# UART6 register map
Registers from a debugger description file.
Registers are 32-bit, access not given, no defined reset value unless marked. A register's access mark holds for its fields unless they carry their own. Addresses are absolute; registers are grouped by the start of their names; lines under a group give offsets from that group; [hi:lo] are bit positions; {n}, {i} and the like mark numbered series; 'fields as' and 'values as' point back to an identical list; <NAME> marks a mode.

## UART6
0x50002000 UART6/DLL
  [7:0] DLL
0x50002000 UART6/THR
  [7:0] THR
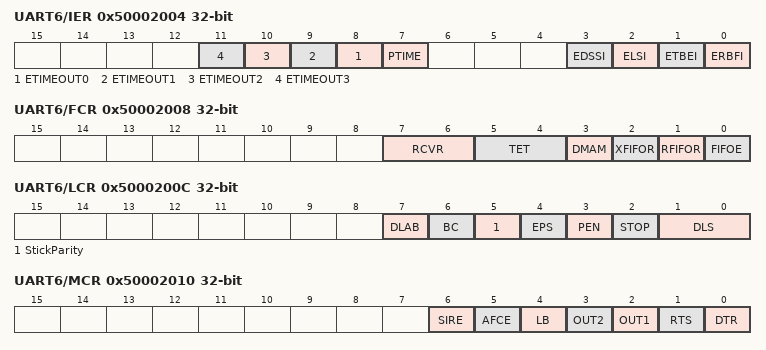
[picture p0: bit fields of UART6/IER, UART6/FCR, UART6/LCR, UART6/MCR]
0x50002004 UART6/IER
  [n+8] ETIMEOUT{n} (n=0..3), [7] PTIME, [3] EDSSI, [2] ELSI, [1] ETBEI, [0] ERBFI
0x50002004 UART6/DLH
  [7:0] DLH
0x50002008 UART6/FCR
  [7:6] RCVR, [5:4] TET, [3] DMAM, [2] XFIFOR, [1] RFIFOR, [0] FIFOE
0x5000200C UART6/LCR
  [7] DLAB, [6] BC, [5] StickParity, [4] EPS, [3] PEN, [2] STOP, [1:0] DLS
0x50002010 UART6/MCR
  [6] SIRE, [5] AFCE, [4] LB, [3] OUT2, [2] OUT1, [1] RTS, [0] DTR
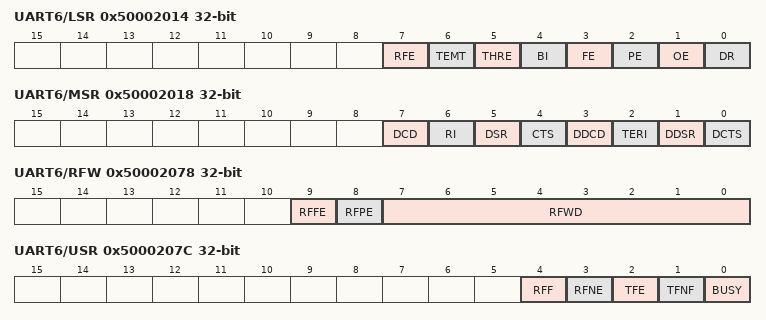
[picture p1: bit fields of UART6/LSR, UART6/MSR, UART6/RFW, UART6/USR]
0x50002014 UART6/LSR ro
  [7] RFE, [6] TEMT, [5] THRE, [4] BI, [3] FE, [2] PE, [1] OE, [0] DR
0x50002018 UART6/MSR ro
  [7] DCD, [6] RI, [5] DSR, [4] CTS, [3] DDCD, [2] TERI, [1] DDSR, [0] DCTS
0x5000201C UART6/SCR
  [7:0] SCR
0x50002030 UART6/STHR
  [7:0] STHR
0x50002070 UART6/FAR
  [0] FAR
0x50002074 UART6/TFR ro
  [7:0] TFR
0x50002078 UART6/RFW
  [9] RFFE, [8] RFPE, [7:0] RFWD
0x5000207C UART6/USR ro
  [4] RFF, [3] RFNE, [2] TFE, [1] TFNF, [0] BUSY
0x50002080 UART6/TFL ro
  [4:0] TFL
0x50002084 UART6/RFL ro
  [4:0] RFL
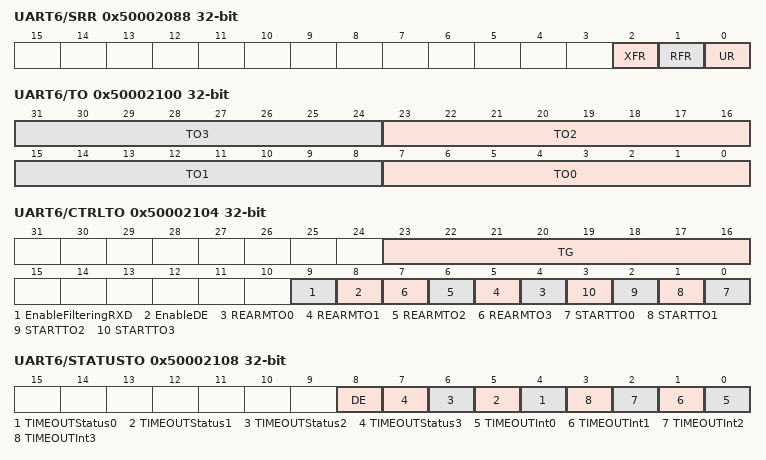
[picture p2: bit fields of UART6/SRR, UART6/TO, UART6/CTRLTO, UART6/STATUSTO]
0x50002088 UART6/SRR
  [2] XFR, [1] RFR, [0] UR
0x5000208C UART6/SRTS
  [0] SRTS
0x50002090 UART6/SBCR
  [0] SBCR
0x50002098 UART6/SFE
  [0] SFE
0x5000209C UART6/SRT
  [1:0] SRCVR
0x500020A0 UART6/STET
  [1:0] STET
0x500020A4 UART6/HTX
  [0] HTX
0x500020A8 UART6/DMASA
  [0] DMASA
0x500020F8 UART6/UCV ro
  [31:0] Version
0x500020FC UART6/CTR ro
  [31:0] ID
0x50002100 UART6/TO
  [8n+7:8n] TO{n} (n=0..3)
0x50002104 UART6/CTRLTO
  [23:16] TG, [9] EnableFilteringRXD, [8] EnableDE, [n+4] REARMTO{n} (n=0..3), [n] STARTTO{n} (n=0..3)
0x50002108 UART6/STATUSTO
  [8] DE, [n+4] TIMEOUTStatus{n} (n=0..3), [n] TIMEOUTInt{n} (n=0..3)
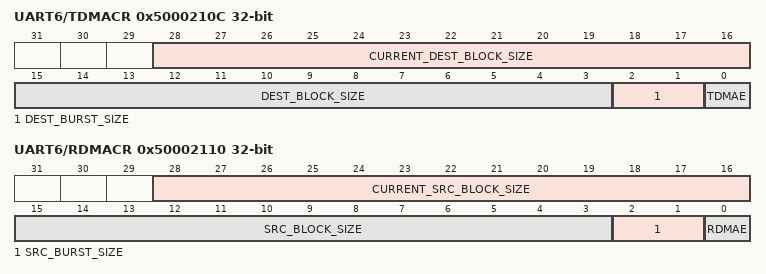
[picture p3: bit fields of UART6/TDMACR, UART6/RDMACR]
0x5000210C UART6/TDMACR
  [28:16] CURRENT_DEST_BLOCK_SIZE, [15:3] DEST_BLOCK_SIZE, [2:1] DEST_BURST_SIZE, [0] TDMAE
0x50002110 UART6/RDMACR
  [28:16] CURRENT_SRC_BLOCK_SIZE, [15:3] SRC_BLOCK_SIZE, [2:1] SRC_BURST_SIZE, [0] RDMAE
